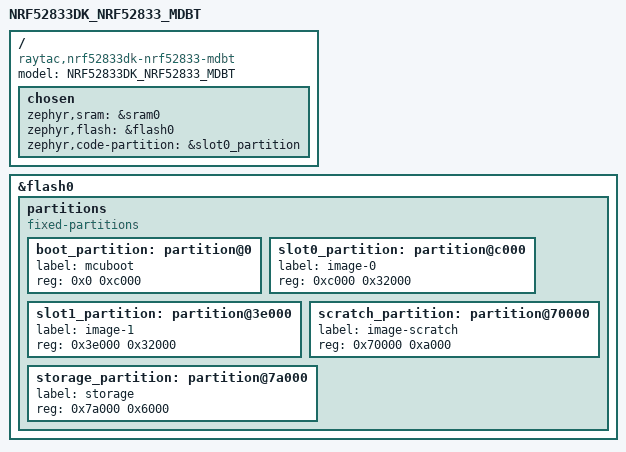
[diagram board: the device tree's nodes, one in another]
// Copyright (c) 2022 Nordic Semiconductor ASA
// SPDX-License-Identifier: Apache-2.0

/dts-v1/;
#include <nordic/nrf52833_qiaa.dtsi>

/ {
	model = "NRF52833DK_NRF52833_MDBT";
	compatible = "raytac,nrf52833dk-nrf52833-mdbt";

	chosen {
		zephyr,sram = &sram0;
		zephyr,flash = &flash0;
		zephyr,code-partition = &slot0_partition;
	};
};

&flash0 {
	partitions {
		compatible = "fixed-partitions";
		#address-cells = <1>;
		#size-cells = <1>;

		boot_partition: partition@0 {
			label = "mcuboot";
			reg = <0x0 0xc000>;
		};
		slot0_partition: partition@c000 {
			label = "image-0";
			reg = <0xc000 0x32000>;
		};
		slot1_partition: partition@3e000 {
			label = "image-1";
			reg = <0x3e000 0x32000>;
		};
		scratch_partition: partition@70000 {
			label = "image-scratch";
			reg = <0x70000 0xa000>;
		};
		storage_partition: partition@7a000 {
			label = "storage";
			reg = <0x7a000 0x6000>;
		};
	};
};

